# HSI_PORTS register map
Vendor: Texas Instruments
Peripheral module from a debugger description file (folder omap4430).
Registers are 32-bit, read-only, reset 0x0 unless marked. A register's access mark holds for its fields unless they carry their own. Offsets are as the file gives them; lines under a group give offsets from that group; [hi:lo] are bit positions; {n}, {i} and the like mark numbered series; 'fields as' and 'values as' point back to an identical list; <NAME> marks a mode.

## HSI_PORTS
0x00 HST_ID_P1 reset not defined — legacy identification on port 1
  [31:0] ID_VAL — Legacy ID
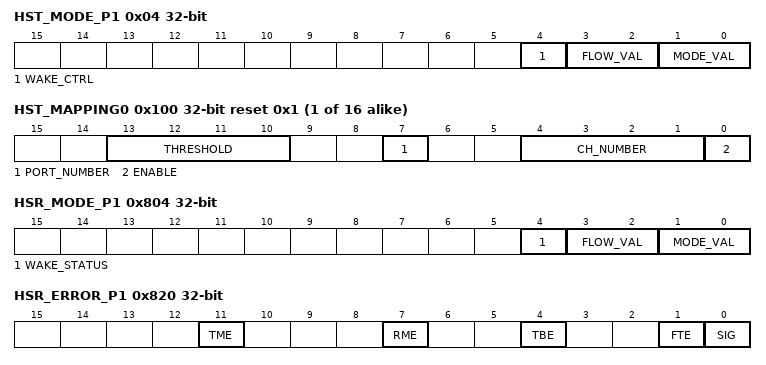
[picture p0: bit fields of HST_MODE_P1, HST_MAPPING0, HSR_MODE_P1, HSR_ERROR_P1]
0x04 HST_MODE_P1 access per field — Defines operation mode and data flow on port 1
  [4] WAKE_CTRL rw — Wake control
    0=software control; 1=automatic control
  [3:2] FLOW_VAL rw — Flow
    0=synchronized; 1=pipelined; 2=real-time
  [1:0] MODE_VAL rw — Mode
    0=sleep; 1=stream; 2=frame
0x08 HST_FRAMESIZE_P1 reset 0x1F — This register is provided for legacy and possible future extension of protocol. Returns 0x1f
  [4:0] SIZE_VAL — In the current implementation it must be always written 31, meaning the frame payload size is 32 bit.
    31=SIZE_VAL_31_r (only possible value)
0x0C HST_TXSTATE_P1 — Define the state of the transmitter on port 1
  [2:0] TXSTATEVAL — State of the transmitter
    0=TXSTATEVAL_0_r (idle); 1=TXSTATEVAL_1_r (wait); 2=TXSTATEVAL_2_r (transmit); 3=TXSTATEVAL_3_r (start); 4=TXSTATEVAL_4_r (break); 5=TXSTATEVAL_5_r (reserved); 6=TXSTATEVAL_6_r (reserved); 7=TXSTATEVAL_7_r (reserved)
0x10 HST_BUFSTATE_P1 — Transmitter state for FIFO 0..7Each bit gives the state of transmit FIFOs:0x1 FIFO full0x0 FIFO not full
  [7:0] BUFSTATE_VAL — Each bit gives the state of transmit buffer register:0x0: buffer is not full0x1: buffer is full
0x18 HST_DIVISOR_P1 access per field — Transmission bit rate divisor for port 1
  [7:0] TX_RATE_DIV_VAL rw — This bitfield B has a range [0..255] and it programs a division factor [1..256], B+1 example: writing 0 divides by 1, writing 1 divides by 2, writing 2 divides by 3, etc
0x20 HST_BREAK_P1 wo — Transmit break strobe register on port 1
  [0] BREAK_VAL — Send a break signal on the port
    0=BREAK_VAL_0_w (no break); 1=BREAK_VAL_1_w (transmit break)
0x24 HST_CHANNELS_P1 access per field reset 0x1 — Number of active channels on port 1 (this will determine the number of the used channel descriptor bits on the MIPI port as well)It can be 1,2,4,8 or 16.
  [4:0] CHAN_NUM_VAL rw — Number of active channels up to 16
    1=one logical channel used, num. of the channel descriptor bits is 0; 4=four logical channel used, num. of the channel descriptor bits is 2; 4=four logical channel used, num. of the channel descriptor bits is 2; 8=eight logical channel used, num. of the channel descriptor bits is 3; 16=sixteen logical channel used, num. of the channel descriptor bits is 4
0x28 HST_ARBMODE_P1 access per field — Arbitration type for the transmit FIFOs on port 1.
  [0] ARB_VAL rw — Mode
    0=round robin; 1=priority
{0x80+4i} HST_BUFFER_P1_CHN_i_{i} wo (i=0..7) — Transmit register for FIFO 0..7Important:Write access to the register with 0xC and 0xF byteen will load its value into the transmit FIFO.In case of using only 16 bit accesses the lower 2 bytes must be written first (byteen 0x3). Between two consecutive 16 bit FIFO related access there can not be any other FIFO related OCP access!
  [31:0] DATA — 32 bits of data
{0xC0+4i} HST_SWAPBUFFER_P1_CHN_i_{i} wo (i=0..7) — Transmit register with byte swapping for FIFO 0..7Important:Write access to the register with 0x3 and 0xF byteen will load its value into the transmit FIFO.In case of using only 16 bit accesses the upper 2 bytes must be written first (byteen 0xC). Between two consecutive 16 bit FIFO related access there can not be any other FIFO related OCP access!
  [31:0] SWAPDATA — 32 bits of byte-swapped data
{0x100+4i} HST_MAPPING{i} access per field reset 0x1 (i=0..15) — TX FIFO configuration register. One register per FIFO
  [13:10] THRESHOLD rw — Number of empty TX FIFO locations that will activate interrupt or DMA requests. DMA requests (if enabled) or interrupt assertion (if enabled) is triggered if the number of free locations in FIFO is less than the THRESHOLD value. 0x0: less than 8 words in the FIFO 0x1: less than 1 words in the FIFO 0x2: less than 2 words in the FIFO ............................................................... 0x8: less than 8 words in the FIFO 0x9 through 0xF: no request generated
  [7] PORT_NUMBER rw — Associates the FIFO to a HSI port
    0=port 1; 1=port 2
  [4:1] CH_NUMBER rw — Associates the TX FIFO to a HSI logical channel number (0-15):0x0: logical channel number 00x1: logical channel number 10xF: logical channel number 15
  [0] ENABLE rw — Enables the FIFO
    0=disabled; 1=enabled
0x800 HSR_ID_P1 reset not defined — Legacy Identification
  [31:0] ID_VAL — Legacy ID
0x804 HSR_MODE_P1 access per field (reset mask 0xFFFFFFEF) — Defines operation mode and data flow on port 1
  [4] WAKE_STATUS ro — Level of WAKE line
  [3:2] FLOW_VAL rw — Flow
    0=synchronized; 1=pipelined; 2=real-time
  [1:0] MODE_VAL rw — Mode
    0=sleep; 1=stream; 2=frame
0x808 HSR_FRAMESIZE_P1 reset 0x1F — legacy returns 0x1f
  [4:0] SIZE_VAL — 0x1f
0x80C HSR_RXSTATE_P1 — Receiver state on port 1
  [2:0] RXSTATEVAL — State
    0=RXSTATEVAL_0_r (idle); 1=RXSTATEVAL_1_r (receiving); 2=RXSTATEVAL_2_r (finished); 3=RXSTATEVAL_3_r (error); 4=RXSTATEVAL_4_r (halt); 5=RXSTATEVAL_5_r (timeout)
0x810 HSR_BUFSTATE_P1 — State of receiver buffer register for port 1
  [7:0] BUFSTATE_VAL — Each bit gives the state of receiver buffer register:0x0: buffer is not full0x1: buffer is full
0x81C HSR_BREAK_P1 — Break detected on port 1
  [0] BREAK_VAL — Break detected
    0=BREAK_VAL_0_r (No break detected); 1=BREAK_VAL_1_r (Break detected)
0x820 HSR_ERROR_P1 — Error detection state register for port 1
  [11] TME — Tx Mapping Error
  [7] RME — Rx Mapping Error
  [4] TBE — Tailing Bit Error
  [1] FTE — Frame Timeout Error
  [0] SIG — signal error (legacy)
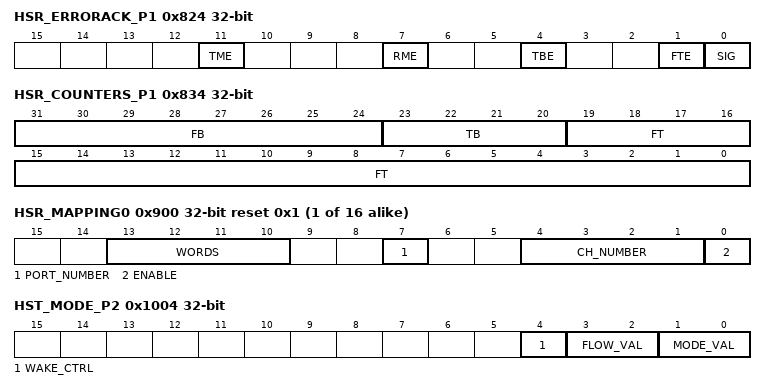
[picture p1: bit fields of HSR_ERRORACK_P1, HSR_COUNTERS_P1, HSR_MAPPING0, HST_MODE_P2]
0x824 HSR_ERRORACK_P1 wo — Error detection acknowledge register on port 1: write 1 to clear
  fields as HSR_ERROR_P1
0x828 HSR_CHANNELS_P1 access per field reset 0x1 — Number of active channels on port 1 (this will determine the number of the used channel descriptor bits on the MIPI port as well)It can be 1,2,4,8 or 16.
  [4:0] CHAN_NUM_VAL rw — Number of active channels
    1=one logical channel used, num. of the channel descriptor bits is 0; 2=two logical channel used, num. of the channel descriptor bits is 1; 4=four logical channel used, num. of the channel descriptor bits is 2; 8=eight logical channel used, num. of the channel descriptor bits is 3; 16=sexteen logical channel used, num. of the channel descriptor bits is 4
0x82C HSR_OVERRUN_P1 — Overrun detection state register for those receive FIFOs which are mapped to port 1.
  [15:0] OVERRUN_VAL — Bit n is set when overrun is detected on channel n
    1=OVERRUN_VAL_1_r (overrun detected); 0=OVERRUN_VAL_0_r (no overrun)
0x830 HSR_OVERRUNACK_P1 access per field — Overrun acknowledge register for those receive FIFOs which are mapped to port 1.
  [15:0] OVERRUNACK_VAL wo — Bit n is set when overrun is acknowledged on channel n
    0=OVERRUNACK_VAL_0_w (no action); 1=OVERRUNACK_VAL_1_w (overrun acknowledge)
0x834 HSR_COUNTERS_P1 rw — Counters setting register for port 1
  [31:24] FB — Setting for Frame Burst Counter. Set n as a value will result the n+1 counter value.
  [23:20] TB — Setting for Tailing Bit Counter. Set n as a value will result the n+1 counter value.
  [19:0] FT — Setting for Frame Timeout counter. Set n as a value will result the n+1 counter value.
{0x880+4i} HSR_BUFFER_P1_CHN_i_{i} reset not defined (i=0..7) — Receive register for receive FIFO 0..7Important:Read access to the register with 0xC and 0xF byteen will remove the receive FIFO related item.In case of using only 16 bit accesses the lower 2 bytes must be read first (byteen 0x3). Between two consecutive 16 bit FIFO related access there can not be any other FIFO related OCP access!
  [31:0] DATA — Received data
{0x8C0+4i} HSR_SWAPBUFFER_P1_CHN_i_{i} reset not defined (i=0..7) — Byte swapped receive register for receive FIFO 0..7Important:Read access to the register with 0x3 and 0xF byteen will remove the receive FIFO related item.In case of using only 16 bit accesses the upper 2 bytes must be read first (byteen 0xC). Between two consecutive 16 bit FIFO related access there can not be any other FIFO related OCP access!
  [31:0] SWAPDATA — Received data swapped
{0x900+4i} HSR_MAPPING{i} access per field reset 0x1 (i=0..15) — RX FIFO Configuration register. One register per FIFO
  [13:10] WORDS ro — Number of words available in the RX FIFO for reading R
  [7] PORT_NUMBER rw — Associates the RX FIFO to a HSI port
    0=port 1; 1=port 2
  [4:1] CH_NUMBER rw — Associates RX FIFO to a HSI logical channel0x0: logical channel number 00x1: logical channel number 10xF: logical channel number 15
  [0] ENABLE rw — Enables or disables RX FIFO
    0=disabled; 1=enabled
0x944 HSR_DLL — Reserved
0x94C HSR_DIVISOR_P1 access per field — Receive bit rate divisor for port 1.This needs to be set for correct protocol timing detection (tailing timeout, frame timeout).
  [7:0] RX_RATE_DIV_VAL rw — The functional clock source divided by this value will be used as a clock base for the receive counters.Set n as a value will result the n+1 divisor value.
0x1000 HST_ID_P2 reset not defined — legacy identification on port 2
  [31:0] ID_VAL — Legacy ID
0x1004 HST_MODE_P2 access per field — Defines operation mode and data flow on port 2
  fields as HST_MODE_P1
0x1008 HST_FRAMESIZE_P2 reset 0x1F — This register is provided for legacy and possible future extension of protocol. Returns 0x1f
  fields as HST_FRAMESIZE_P1
0x100C HST_TXSTATE_P2 — Define the state of the transmitter on port 2
  fields as HST_TXSTATE_P1
0x1010 HST_BUFSTATE_P2 — Transmitter state for buffer 8..15Each bit gives the state of transmit FIFOs:0x1 FIFO full0x0 FIFO not full
  fields as HST_BUFSTATE_P1
0x1018 HST_DIVISOR_P2 access per field — Transmission bit rate divisor for port 2
  fields as HST_DIVISOR_P1
0x1020 HST_BREAK_P2 wo — Transmit break strobe register on port 2
  fields as HST_BREAK_P1
0x1024 HST_CHANNELS_P2 access per field reset 0x1 — Number of active channels on port 2 (this will determine the number of the used channel descriptor bits on the MIPI port as well)It can be 1,2,4,8 or 16.
  fields as HST_CHANNELS_P1
0x1028 HST_ARBMODE_P2 access per field — Arbitration type for the transmit FIFOs on port 2.
  [0] ARB_VAL rw — Mode
    0=round robin; 1=priority
{0x1080+4i} HST_BUFFER_P2_CHN_i_{i} wo (i=0..7) — Transmit register for FIFO 8..15Important:Write access to the register with 0xC and 0xF byteen will load its value into the transmit FIFO.In case of using only 16 bit accesses the lower 2 bytes must be written first (byteen 0x3). Between two consecutive 16 bit FIFO related access there can not be any other FIFO related OCP access!
  [31:0] DATA — 32 bits of data
{0x10C0+4i} HST_SWAPBUFFER_P2_CHN_i_{i} wo (i=0..7) — Transmit register with byte swapping for FIFO 8..15Important:Write access to the register with 0x3 and 0xF byteen will load its value into the transmit FIFO.In case of using only 16 bit accesses the upper 2 bytes must be written first (byteen 0xC). Between two consecutive 16 bit FIFO related access there can not be any other FIFO related OCP access!
  [31:0] SWAPDATA — 32 bits of byte-swapped data
0x1800 HSR_ID_P2 reset not defined — Legacy Identification
  [31:0] ID_VAL — Legacy ID
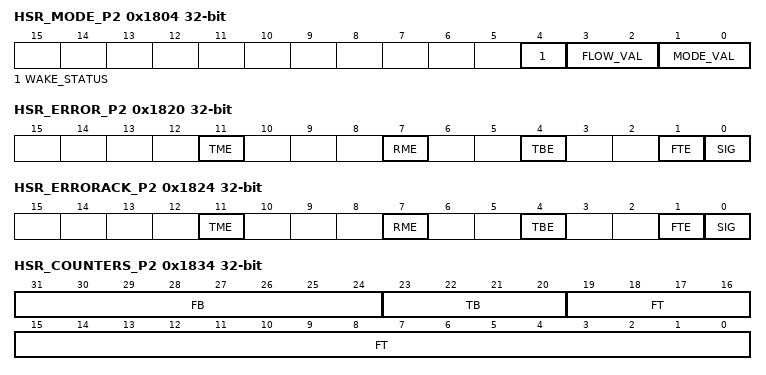
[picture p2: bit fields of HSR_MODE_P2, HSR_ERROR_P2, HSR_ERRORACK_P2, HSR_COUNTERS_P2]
0x1804 HSR_MODE_P2 access per field (reset mask 0xFFFFFFEF) — Defines operation mode and data flow on port 2
  fields as HSR_MODE_P1
0x1808 HSR_FRAMESIZE_P2 reset 0x1F — legacy returns 0x1f
  [4:0] SIZE_VAL — 0x1f
0x180C HSR_RXSTATE_P2 — Receiver state on port 2
  fields as HSR_RXSTATE_P1
0x1810 HSR_BUFSTATE_P2 — State of receiver buffer register for port 2
  fields as HSR_BUFSTATE_P1
0x181C HSR_BREAK_P2 — Break detected on port 2
  fields as HSR_BREAK_P1
0x1820 HSR_ERROR_P2 — Error detection state register for port 2
  fields as HSR_ERROR_P1
0x1824 HSR_ERRORACK_P2 wo — Error detection acknowledge register on port 2: write 1 to clear
  fields as HSR_ERROR_P1
0x1828 HSR_CHANNELS_P2 access per field reset 0x1 — Number of active channels on port 2 (this will determine the number of the used channel descriptor bits on the MIPI port as well)It can be 1,2,4,8 or 16.
  fields as HSR_CHANNELS_P1
0x182C HSR_OVERRUN_P2 — Overrun detection state register for those receive FIFOs which are mapped to port 2.
  fields as HSR_OVERRUN_P1
0x1830 HSR_OVERRUNACK_P2 access per field — Overrun acknowledge register for those receive FIFOs which are mapped to port 2.
  fields as HSR_OVERRUNACK_P1
0x1834 HSR_COUNTERS_P2 rw — Counters setting register for port 2
  fields as HSR_COUNTERS_P1
{0x1880+4i} HSR_BUFFER_P2_CHN_i_{i} reset not defined (i=0..7) — Receive register for receive FIFO 8..15Important:Read access to the register with 0xC and 0xF byteen will remove the receive FIFO related item.In case of using only 16 bit accesses the lower 2 bytes must be read first (byteen 0x3). Between two consecutive 16 bit FIFO related access there can not be any other FIFO related OCP access!
  [31:0] DATA — Received data
{0x18C0+4i} HSR_SWAPBUFFER_P2_CHN_i_{i} reset not defined (i=0..7) — Byte swapped receive register for receive FIFO 8..15Important:Read access to the register with 0x3 and 0xF byteen will remove the receive FIFO related item.In case of using only 16 bit accesses the upper 2 bytes must be read first (byteen 0xC). Between two consecutive 16 bit FIFO related access there can not be any other FIFO related OCP access!
  [31:0] SWAPDATA — Received data swapped
0x194C HSR_DIVISOR_P2 access per field — Receive bit rate divisor for port 2.This needs to be set for correct protocol timing detection (tailing timeout, frame timeout).
  fields as HSR_DIVISOR_P1
